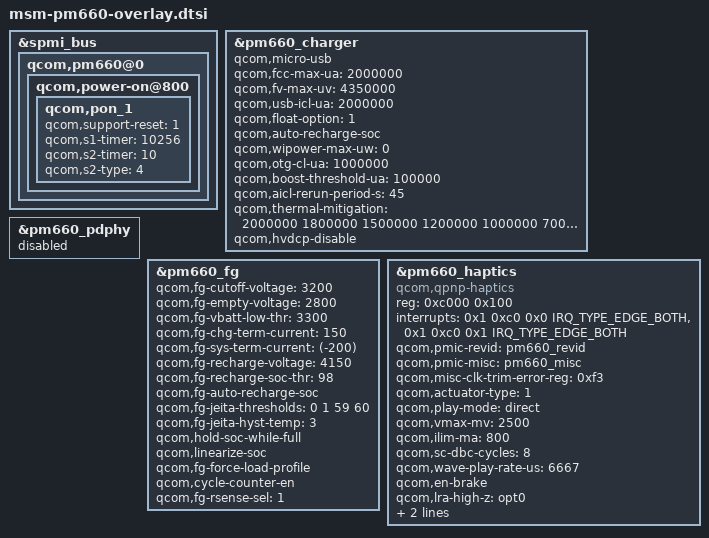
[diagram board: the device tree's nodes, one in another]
/* Copyright (c) 2016-2017, The Linux Foundation. All rights reserved.
 *
 * This program is free software; you can redistribute it and/or modify
 * it under the terms of the GNU General Public License version 2 and
 * only version 2 as published by the Free Software Foundation.
 *
 * This program is distributed in the hope that it will be useful,
 * but WITHOUT ANY WARRANTY; without even the implied warranty of
 * MERCHANTABILITY or FITNESS FOR A PARTICULAR PURPOSE.  See the
 * GNU General Public License for more details.
 */

&spmi_bus {
	qcom,pm660@0 {
		qcom,power-on@800 {
			qcom,pon_1 {
				qcom,support-reset = <1>;
				qcom,s1-timer = <10256>;
				qcom,s2-timer = <10>;
				qcom,s2-type = <4>;
			};
		};
	};
};

&pm660_charger {
	qcom,micro-usb;
	qcom,fcc-max-ua = <2000000>;
	qcom,fv-max-uv = <4350000>;
	qcom,usb-icl-ua = <2000000>;
	qcom,float-option = <1>;
	qcom,auto-recharge-soc;
	qcom,wipower-max-uw = <0>;
	qcom,otg-cl-ua = <1000000>;
	qcom,boost-threshold-ua = <100000>;
	qcom,aicl-rerun-period-s = <45>;
	qcom,thermal-mitigation = <2000000 1800000 1500000 1200000 
                               1000000 700000 500000 300000>;
	qcom,hvdcp-disable;
    /delete-property/ qcom,hvdcp-autonomous;
};

&pm660_pdphy {
	status = "disabled";
};

&pm660_fg {
    status = "okay";
    
    qcom,fg-cutoff-voltage = <3200>; 
    qcom,fg-empty-voltage = <2800>;
    qcom,fg-vbatt-low-thr = <3300>;
    qcom,fg-chg-term-current = <150>;
    qcom,fg-sys-term-current = <(-200)>;
    qcom,fg-recharge-voltage = <4150>;
    qcom,fg-recharge-soc-thr = <98>;
    qcom,fg-auto-recharge-soc;
    qcom,fg-jeita-thresholds = <0 1 59 60>;
    qcom,fg-jeita-hyst-temp = <3>;
    qcom,hold-soc-while-full;
    qcom,linearize-soc;
    qcom,fg-force-load-profile;
    qcom,cycle-counter-en;
    qcom,fg-rsense-sel = <1>;
};

&pm660_haptics {
        // leds-qpnp-vibrator  
	/*
	status = "okay";
	compatible = "qcom,qpnp-vibrator";
	reg = <0xc000 0x100>;
	label = "vibrator";
	qcom,vib-timeout-ms = <15000>;
	qcom,vib-vtg-level-mV = <3100>;
	qcom,mode = "manual"; */
	
	// led-qpnp-haptics
	compatible = "qcom,qpnp-haptics";
	reg = <0xc000 0x100>;
	interrupts = <0x1 0xc0 0x0 IRQ_TYPE_EDGE_BOTH>,
			<0x1 0xc0 0x1 IRQ_TYPE_EDGE_BOTH>;
	interrupt-names = "hap-sc-irq", "hap-play-irq";
	qcom,pmic-revid = <&pm660_revid>;
	qcom,pmic-misc = <&pm660_misc>;
	qcom,misc-clk-trim-error-reg = <0xf3>;
	qcom,actuator-type = <1>;
	qcom,play-mode = "direct";
	qcom,vmax-mv = <2500>;
	qcom,ilim-ma = <800>;
	qcom,sc-dbc-cycles = <8>;
	qcom,wave-play-rate-us = <6667>;
	qcom,en-brake;
	qcom,lra-high-z = "opt0";
	qcom,lra-auto-res-mode = "qwd";
	qcom,lra-res-cal-period = <4>;
};
